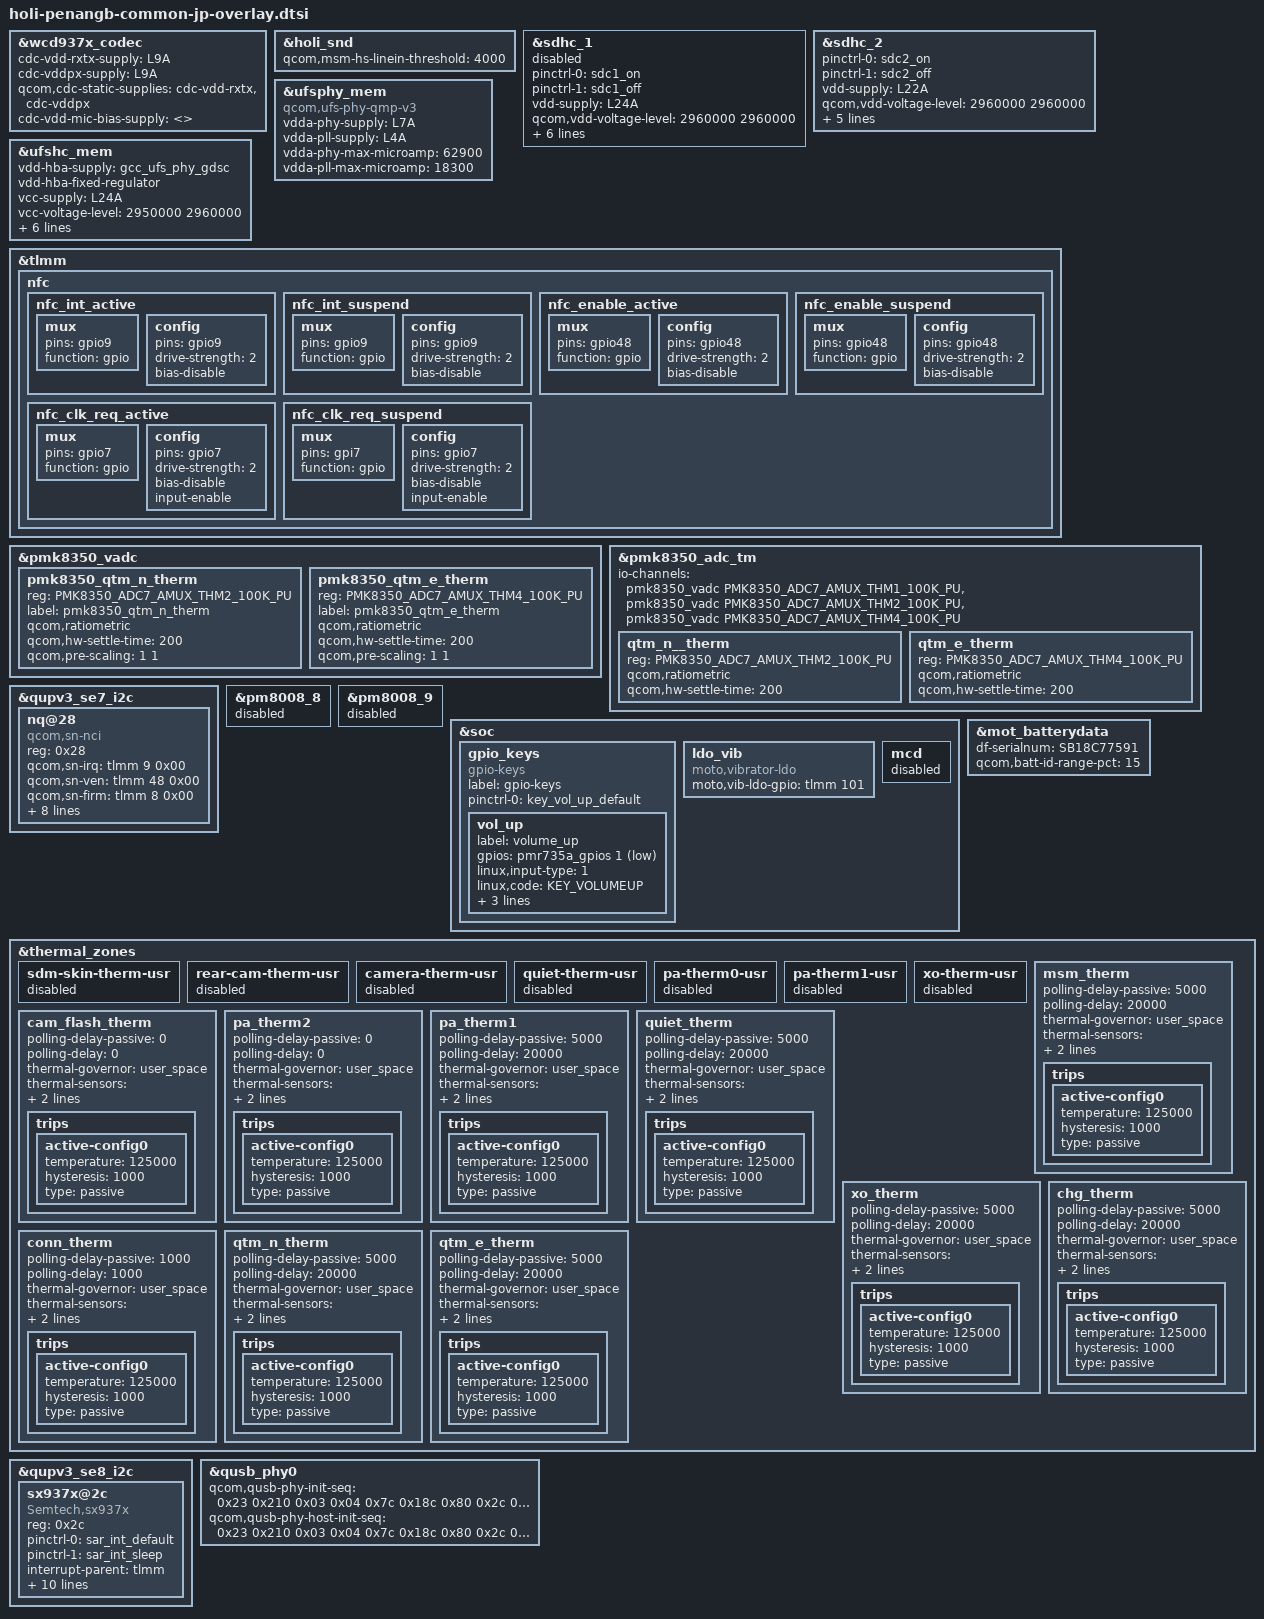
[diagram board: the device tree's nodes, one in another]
/* Copyright (c) 2021, The Linux Foundation. All rights reserved.
 *
 * This program is free software; you can redistribute it and/or modify
 * it under the terms of the GNU General Public License version 2 and
 * only version 2 as published by the Free Software Foundation.
 *
 * This program is distributed in the hope that it will be useful,
 * but WITHOUT ANY WARRANTY; without even the implied warranty of
 * MERCHANTABILITY or FITNESS FOR A PARTICULAR PURPOSE.  See the
 * GNU General Public License for more details.
 */
#include "holi-audio-penang-overlay.dtsi"
#include "holi-nopmi-moto-common-overlay.dtsi"

#include <dt-bindings/gpio/gpio.h>
#include <dt-bindings/input/linux-event-codes.h>
#include "holi-pmic-overlay-pm6125.dtsi"
#include "holi-thermal-overlay-pm6125.dtsi"
#include "display/holi-sde-display-mtp-pm6125.dtsi"
#include "penang-fps-overlay.dtsi"
#include "penang-display.dtsi"
#include "penang-touchscreen.dtsi"
#include "penang-fmr-overlay.dtsi"
#include "camera/holi-camera-sensor-mot-penang-jp-overlay.dtsi"
#include "discrete_charging_penang.dtsi"
#include "moto_therm_sys_temp.dtsi"

&wcd937x_codec {
	cdc-vdd-rxtx-supply = <&L9A>;
	cdc-vddpx-supply = <&L9A>;
	qcom,cdc-static-supplies = "cdc-vdd-rxtx",
				   "cdc-vddpx";
	/*
	 * Overriding cdc-vdd-mic-bias-supply to dummy value
	 * to avoid compilation errors as BOB is not definied
	 * for pm6125
	 */
	cdc-vdd-mic-bias-supply = <>;
};

&holi_snd {
	qcom,msm-hs-linein-threshold = <4000>;
};

/* Dummy LDO reference */
&sdhc_1 {
	status = "disabled";

	pinctrl-names = "default", "sleep";
	pinctrl-0 = <&sdc1_on>;
	pinctrl-1 = <&sdc1_off>;

	vdd-supply = <&L24A>;
	qcom,vdd-voltage-level = <2960000 2960000>;
	qcom,vdd-current-level = <0 570000>;

	vdd-io-supply = <&L11A>;
	qcom,vdd-io-always-on;
	qcom,vdd-io-lpm-sup;
	qcom,vdd-io-voltage-level = <1800000 1800000>;
	qcom,vdd-io-current-level = <0 325000>;
};

&sdhc_2 {
	status = "ok";

	pinctrl-names = "default", "sleep";
	pinctrl-0 = <&sdc2_on>;
	pinctrl-1 = <&sdc2_off>;

	vdd-supply = <&L22A>;
	qcom,vdd-voltage-level = <2960000 2960000>;
	qcom,vdd-current-level = <0 800000>;

	vdd-io-supply = <&L5A>;
	qcom,vdd-io-voltage-level = <1800000 2960000>;
	qcom,vdd-io-current-level = <0 22000>;

	cd-gpios = <&tlmm 94 GPIO_ACTIVE_HIGH>;
};

&ufsphy_mem {
		compatible = "qcom,ufs-phy-qmp-v3";

		vdda-phy-supply = <&L7A>;
		vdda-pll-supply = <&L4A>;
		vdda-phy-max-microamp = <62900>;
		vdda-pll-max-microamp = <18300>;

		status = "ok";
};

&ufshc_mem {
		vdd-hba-supply = <&gcc_ufs_phy_gdsc>;
		vdd-hba-fixed-regulator;

		vcc-supply = <&L24A>;
		vcc-voltage-level = <2950000 2960000>;
		vcc-max-microamp = <800000>;

		vccq2-supply = <&L11A>;
		vccq2-max-microamp = <800000>;
		vccq2-voltage-level = <1800000 1800000>;

		qcom,vddp-ref-clk-supply = <&L4A>;
		qcom,vddp-ref-clk-max-microamp = <100>;

		status = "ok";
};


&tlmm {

	nfc {
		nfc_int_active: nfc_int_active {
			/* active state */
			mux {
				/* GPIO 9: NFC Read Interrupt */
				pins = "gpio9";
				function = "gpio";
			};

			config {
				pins = "gpio9";
				drive-strength = <2>; /* 2 MA */
				bias-disable;
			};
		};

		nfc_int_suspend: nfc_int_suspend {
			/* sleep state */
			mux {
				/* GPIO 9: NFC Read Interrupt */
				pins = "gpio9";
				function = "gpio";
			};

			config {
				pins = "gpio9";
				drive-strength = <2>; /* 2 MA */
				bias-disable;
			};
		};

		nfc_enable_active: nfc_enable_active {
			mux {
				/* 48: Enable, 8: Firmware*/
				pins = "gpio48";
				function = "gpio";
			};

			config {
				pins = "gpio48";
				drive-strength = <2>; /* 2 MA */
				bias-disable;
			};
		};

		nfc_enable_suspend: nfc_enable_suspend {
			mux {
				/* 48: Enable, 8: Firmware */
				pins = "gpio48";
				function = "gpio";
			};

			config {
				pins = "gpio48";
				drive-strength = <2>; /* 2 MA */
				bias-disable;
			};
		};


		nfc_clk_req_active: nfc_clk_req_active {
			/* active state */
			mux {
				/* GPIO 7: NFC CLK Req*/
				pins = "gpio7";
				function = "gpio";
			};

			config {
				pins = "gpio7";
				drive-strength = <2>; /* 2 MA */
				bias-disable;
				input-enable;
			};
		};

		nfc_clk_req_suspend: nfc_clk_req_suspend {
			/* sleep state */
			mux {
				/* GPIO 7: NFC CLK Req */
				pins = "gpi7";
				function = "gpio";
			};

			config {
				pins = "gpio7";
				drive-strength = <2>; /* 2 MA */
				bias-disable;
				input-enable;
			};
		};
	};
};

&pmk8350_vadc {
	pmk8350_qtm_n_therm {
		reg = <PMK8350_ADC7_AMUX_THM2_100K_PU>;
		label = "pmk8350_qtm_n_therm";
		qcom,ratiometric;
		qcom,hw-settle-time = <200>;
		qcom,pre-scaling = <1 1>;
	};
	pmk8350_qtm_e_therm {
		reg = <PMK8350_ADC7_AMUX_THM4_100K_PU>;
		label = "pmk8350_qtm_e_therm";
		qcom,ratiometric;
		qcom,hw-settle-time = <200>;
		qcom,pre-scaling = <1 1>;
	};
};

&pmk8350_adc_tm {
	io-channels = <&pmk8350_vadc PMK8350_ADC7_AMUX_THM1_100K_PU>,
			<&pmk8350_vadc PMK8350_ADC7_AMUX_THM2_100K_PU>,
			<&pmk8350_vadc PMK8350_ADC7_AMUX_THM4_100K_PU>;

	qtm_n__therm {
		reg = <PMK8350_ADC7_AMUX_THM2_100K_PU>;
		qcom,ratiometric;
		qcom,hw-settle-time = <200>;
	};
	qtm_e_therm {
		reg = <PMK8350_ADC7_AMUX_THM4_100K_PU>;
		qcom,ratiometric;
		qcom,hw-settle-time = <200>;
	};
};

&qupv3_se7_i2c {
	status = "ok";
	#address-cells = <1>;
	#size-cells = <0>;
	nq@28 {
		compatible = "qcom,sn-nci";
		reg = <0x28>;
		qcom,sn-irq = <&tlmm 9 0x00>;
		qcom,sn-ven = <&tlmm 48 0x00>;
		qcom,sn-firm = <&tlmm 8 0x00>;
		qcom,sn-clkreq = <&tlmm 7 0x00>;
		qcom,sn-vdd-1p8-supply = <&L9A>;
		qcom,sn-vdd-1p8-voltage = <1800000 1800000>;
		qcom,sn-vdd-1p8-current = <157000>;
		interrupt-parent = <&tlmm>;
		interrupts = <9 0>;
		interrupt-names = "nfc_irq";
		pinctrl-names = "nfc_active", "nfc_suspend";
		pinctrl-0 = <&nfc_int_active &nfc_enable_active>;
		pinctrl-1 = <&nfc_int_suspend &nfc_enable_suspend>;
	};
};



&pm8008_8 {
	status = "disabled";
};

&pm8008_9 {
	status = "disabled";
};

&soc {
	gpio_keys {
		compatible = "gpio-keys";
		label = "gpio-keys";

		pinctrl-names = "default";
		pinctrl-0 = <&key_vol_up_default>;

		vol_up {
			label = "volume_up";
			gpios = <&pmr735a_gpios 1 GPIO_ACTIVE_LOW>;
			linux,input-type = <1>;
			linux,code = <KEY_VOLUMEUP>;
			gpio-key,wakeup;
			debounce-interval = <15>;
			linux,can-disable;
		};
	};

	ldo_vib {
		compatible = "moto,vibrator-ldo";
		moto,vib-ldo-gpio = <&tlmm 101 0x0>;
		status = "ok";
	};

	mcd {
		 status = "disabled";
	};
};

&mot_batterydata {
	df-serialnum = "SB18C77591";
	qcom,batt-id-range-pct = <15>;
	#include "qg-batterydata-jk50-atl-5000mah.dtsi"
	#include "qg-batterydata-jk50-scud-5000mah.dtsi"
};

&thermal_zones {
	sdm-skin-therm-usr {
		status = "disabled";
	};
	rear-cam-therm-usr {
		status = "disabled";
	};
	camera-therm-usr {
		status = "disabled";
	};
	quiet-therm-usr {
		status = "disabled";
	};
	pa-therm0-usr {
		status = "disabled";
	};
	pa-therm1-usr {
		status = "disabled";
	};
	xo-therm-usr {
		status = "disabled";
	};

	msm_therm {
                polling-delay-passive = <5000>;
                polling-delay = <20000>;
                thermal-governor = "user_space";
                thermal-sensors = <&pm6125_adc_tm_iio ADC5_GPIO1_100K_PU>;
                wake-capable-sensor;
                trips {
                        active-config0 {
                                temperature = <125000>;
                                hysteresis = <1000>;
                                type = "passive";
                        };
                };
        };

	cam_flash_therm {
                polling-delay-passive = <0>;
                polling-delay = <0>;
                thermal-governor = "user_space";
                thermal-sensors = <&pm6125_adc_tm ADC5_GPIO3_100K_PU>;
                wake-capable-sensor;
                trips {
                        active-config0 {
                                temperature = <125000>;
                                hysteresis = <1000>;
                                type = "passive";
                        };
                };
        };

	pa_therm2 {
                polling-delay-passive = <0>;
                polling-delay = <0>;
                thermal-governor = "user_space";
                thermal-sensors = <&pm6125_adc_tm ADC5_GPIO4_100K_PU>;
                wake-capable-sensor;
                trips {
                        active-config0 {
                                temperature = <125000>;
                                hysteresis = <1000>;
                                type = "passive";
                        };
                };
        };

	pa_therm1 {
                polling-delay-passive = <5000>;
                polling-delay = <20000>;
                thermal-governor = "user_space";
                thermal-sensors = <&pm6125_adc_tm ADC5_AMUX_THM1_100K_PU>;
                wake-capable-sensor;
                trips {
                        active-config0 {
                                temperature = <125000>;
                                hysteresis = <1000>;
                                type = "passive";
                        };
                };
        };

        quiet_therm {
                polling-delay-passive = <5000>;
                polling-delay = <20000>;
                thermal-governor = "user_space";
                thermal-sensors = <&pm6125_adc_tm ADC5_AMUX_THM2_100K_PU>;
                wake-capable-sensor;
                trips {
                        active-config0 {
                                temperature = <125000>;
                                hysteresis = <1000>;
                                type = "passive";
                        };
                };
        };

        xo_therm {
                polling-delay-passive = <5000>;
                polling-delay = <20000>;
                thermal-governor = "user_space";
                thermal-sensors = <&pmk8350_adc_tm PMK8350_ADC7_AMUX_THM1_100K_PU>;
                wake-capable-sensor;
                trips {
                        active-config0 {
                                temperature = <125000>;
                                hysteresis = <1000>;
                                type = "passive";
                        };
                };
        };

	chg_therm {
                polling-delay-passive = <5000>;
                polling-delay = <20000>;
                thermal-governor = "user_space";
                thermal-sensors = <&pmk8350_adc_tm PMK8350_ADC7_AMUX_THM2_100K_PU>;
                wake-capable-sensor;
                trips {
                        active-config0 {
                                temperature = <125000>;
                                hysteresis = <1000>;
                                type = "passive";
                        };
                };
        };

        conn_therm {
                polling-delay-passive = <1000>;
                polling-delay = <1000>;
                thermal-governor = "user_space";
                thermal-sensors = <&pm6125_adc_tm_iio ADC5_GPIO2_100K_PU>;
                wake-capable-sensor;
                trips {
                        active-config0 {
                                temperature = <125000>;
                                hysteresis = <1000>;
                                type = "passive";
                        };
                };
        };

        qtm_n_therm {
                polling-delay-passive = <5000>;
                polling-delay = <20000>;
                thermal-governor = "user_space";
                thermal-sensors = <&pmk8350_adc_tm PMK8350_ADC7_AMUX_THM2_100K_PU>;
                wake-capable-sensor;
                trips {
                        active-config0 {
                                temperature = <125000>;
                                hysteresis = <1000>;
                                type = "passive";
                        };
                };
        };

        qtm_e_therm {
                polling-delay-passive = <5000>;
                polling-delay = <20000>;
                thermal-governor = "user_space";
                thermal-sensors = <&pmk8350_adc_tm PMK8350_ADC7_AMUX_THM4_100K_PU>;
                wake-capable-sensor;
                trips {
                        active-config0 {
                                temperature = <125000>;
                                hysteresis = <1000>;
                                type = "passive";
                        };
                };
        };

};

&qupv3_se8_i2c {

	status = "ok";

	sx937x@2c {
		compatible = "Semtech,sx937x";
		reg = <0x2c>;
		pinctrl-names = "default","sleep";
		pinctrl-0 = <&sar_int_default>;
		pinctrl-1 = <&sar_int_sleep>;
		interrupt-parent = <&tlmm>;
		interrupts = <24 0x02>;
		interrupt-names = "sx937x_irq";
		Semtech,nirq-gpio = <&tlmm 24 0x02>;
                //please fix me
		cap_vdd-supply = <&L9A>;
		/*use PH4/5/6 as the reference sensor
		set it to 0xff if the ref-phases-x is not used*/
		Semtech,ref-phases-a = <5>;
		Semtech,ref-phases-b = <6>;
		Semtech,ref-phases-c = <0xff>;
		Semtech,button-flag = <0x1f>;
		Semtech,reg-num = <64>;
		Semtech,reg-init = <
		0x4004  0x70
		0x4008  0x8
		0x8020  0x32
		0x8028 0x1088E
		0x8034 0x486E
		0x8040 0x1088E
		0x804C 0x4E96
		0x8058 0x446E
		0x8064  0x88E
		0x8070  0x86E
		0x807C  0x85E
		0x8030  0xFFF9FD
		0x803C  0xFEF9FF
		0x8048  0xFFD9FF
		0x8054  0xFFF97F
		0x8060  0xBFF9FF
		0x806C  0xFFF9EF
		0x8078  0xF7F9FF
		0x8084  0xFFFFFF
		0x8098  0x3F2C
		0x80B8  0x3620
		0x80D8  0x3821
		0x80F8  0x2B24
		0x8118  0x263C
		0x8138  0xC8
		0x8158  0xC8
		0x8178  0xC8
		0x80A0  0x222200E1
		0x80C0  0x141400E2
		0x80E0  0x232300E1
		0x8100  0x202000E0
		0x8120  0x2F2F00E2
		0x8140  0x0
		0x8160  0x0
		0x8180  0x0
		0x8188  0x8000015
		0x818C  0x8000016
		0x8190  0x0
		0x8194  0x0
		0x8090  0x54C45000
		0x80B0  0x2AE27000
		0x80D0  0x54D45000
		0x80F0  0x2AE27000
		0x8110  0x2AE27000
		0x8130  0x2AD67000
		0x8150  0x2AD67000
		0x8170  0x2AD66000
		0x8088  0x300000
		0x80A8  0x300000
		0x80C8  0x300000
		0x80E8  0x300000
		0x8108  0x300000
		0x8128  0x300000
		0x8148  0x300000
		0x8168  0x300000
		0x808C  0x60200018
		0x80AC  0x60200018
		0x80CC  0x60200018
		0x80EC  0x60200018
		0x810C  0x60200018
		0x812C  0x60200018
		0x814C  0x60200018
		0x816C  0x60200018
		0x8024  0x7F7F
		>;
		status = "ok";
		};
};

&qusb_phy0 {
	qcom,qusb-phy-init-seq =
		/* <value reg_offset> */
		<0x23 0x210 /* PWR_CTRL1 */
		 0x03 0x04  /* PLL_ANALOG_CONTROLS_TWO */
		 0x7c 0x18c /* PLL_CLOCK_INVERTERS */
		 0x80 0x2c  /* PLL_CMODE */
		 0x0a 0x184 /* PLL_LOCK_DELAY */
		 0x19 0xb4  /* PLL_DIGITAL_TIMERS_TWO */
		 0x40 0x194 /* PLL_BIAS_CONTROL_1 */
		 0x16 0x198 /* PLL_BIAS_CONTROL_2 */
		 0x21 0x214 /* PWR_CTRL2 */
		 0x08 0x220 /* IMP_CTRL1 */
		 0x58 0x224 /* IMP_CTRL2 */
		 0x37 0x240 /* TUNE1 */
		 0x29 0x244 /* TUNE2 */
		 0xca 0x248 /* TUNE3 */
		 0x04 0x24c /* TUNE4 */
		 0x03 0x250 /* TUNE5 */
		 0x30 0x23c /* CHG_CTRL2 */
		 0x22 0x210>; /* PWR_CTRL1 */

	qcom,qusb-phy-host-init-seq =
		/* <value reg_offset> */
		<0x23 0x210 /* PWR_CTRL1 */
		0x03 0x04  /* PLL_ANALOG_CONTROLS_TWO */
		0x7c 0x18c /* PLL_CLOCK_INVERTERS */
		0x80 0x2c  /* PLL_CMODE */
		0x0a 0x184 /* PLL_LOCK_DELAY */
		0x19 0xb4  /* PLL_DIGITAL_TIMERS_TWO */
		0x40 0x194 /* PLL_BIAS_CONTROL_1 */
		0x16 0x198 /* PLL_BIAS_CONTROL_2 */
		0x21 0x214 /* PWR_CTRL2 */
		0x08 0x220 /* IMP_CTRL1 */
		0x58 0x224 /* IMP_CTRL2 */
		0x37 0x240 /* TUNE1 */
		0x2a 0x244 /* TUNE2 */
		0xca 0x248 /* TUNE3 */
		0x04 0x24c /* TUNE4 */
		0x03 0x250 /* TUNE5 */
		0x30 0x23c /* CHG_CTRL2 */
		0x22 0x210>; /* PWR_CTRL1 */
};
